# VPAC0_PAR_VPAC_VISS0_S_VBUSP_K3_GLBCE_TOP_STATMEM_CFG_GLBCE_STATMEM register map
Vendor: Texas Instruments
Peripheral module from a debugger description file (folder J7ES).
Registers are 32-bit, read-write, reset 0x0 unless marked. A register's access mark holds for its fields unless they carry their own. Offsets are as the file gives them; lines under a group give offsets from that group; [hi:lo] are bit positions; {n}, {i} and the like mark numbered series; 'fields as' and 'values as' point back to an identical list; <NAME> marks a mode.

## VPAC0_PAR_VPAC_VISS0_S_VBUSP_K3_GLBCE_TOP_STATMEM_CFG_GLBCE_STATMEM
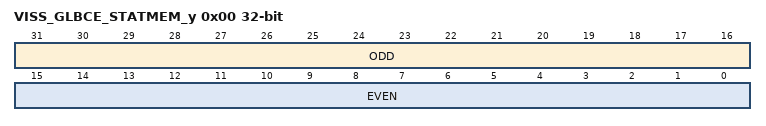
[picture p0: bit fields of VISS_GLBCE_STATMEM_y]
0x00 VISS_GLBCE_STATMEM_y — odd and even banks are combined for one 32-bit access Offset = 00084000h + (y * 4h); where y = 0h to FFFh
  [31:16] ODD — Odd bank
  [15:0] EVEN — Even bank
